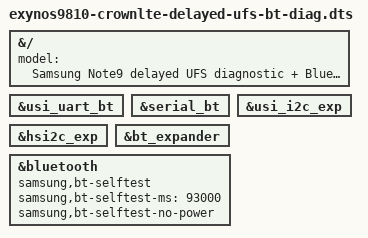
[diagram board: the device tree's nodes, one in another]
// SPDX-License-Identifier: GPL-2.0
/*
 * Bluetooth B1, trial B1-read: the delayed-UFS diagnostic plus the BT UART,
 * the expander bus and the bluetooth rfkill device. Read-only: nothing
 * writes the PCAL6524 (the driver only reads its registers) and BT_REG_ON
 * is left as the bootloader set it. The self-test at 93 s reports the
 * expander reset line, a full expander register dump validated against
 * the probe dump, the BT_REG_ON state, the UART clock and USI wrapper
 * readback and the rfkill index, then
 * "bt selftest: RESULT PASS-NOPOWER, state ON (bootloader)".
 * See Documentation/crownlte/bluetooth-port.md.
 */
#include "exynos9810-crownlte-delayed-ufs-diag.dts"

&{/} {
	model = "Samsung Note9 delayed UFS diagnostic + Bluetooth B1 (read-only)";
};

&usi_uart_bt {
	status = "okay";
};

&serial_bt {
	status = "okay";
};

&usi_i2c_exp {
	status = "okay";
};

&hsi2c_exp {
	status = "okay";
};

&bt_expander {
	status = "okay";
};

&bluetooth {
	samsung,bt-selftest;
	samsung,bt-selftest-ms = <93000>;
	samsung,bt-selftest-no-power;
	status = "okay";
};
